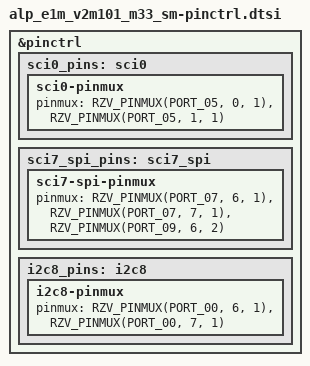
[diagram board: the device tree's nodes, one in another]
/*
 * Copyright (c) 2026 Alp Lab AB
 * SPDX-License-Identifier: Apache-2.0
 */

#include <zephyr/dt-bindings/gpio/gpio.h>
#include <zephyr/dt-bindings/pinctrl/renesas/pinctrl-rzv2n.h>

&pinctrl {
	/* SCI_UART0 console: P50 TXD / P51 RXD */
	sci0_pins: sci0 {
		sci0-pinmux {
			pinmux = <RZV_PINMUX(PORT_05, 0, 1)>, /* TXD */
				 <RZV_PINMUX(PORT_05, 1, 1)>; /* RXD */
		};
	};

	/*
	 * GD32G553 SPI fast path on SCI channel 7 (clock-synchronous Simple-SPI).
	 * Per the RZ/V2N PFC (Table 1.2-3): P76 = TXD7_MOSI7 (func1), P77 =
	 * RXD7_MISO7 (func1), P96 = SCK7 (func2).  Calibrated against the known-good
	 * console pin P50 = TXD0 (func1) and the P52 TXD1/SCK0/DE0/CTS0N column run.
	 *
	 * P97 (SS7) is deliberately NOT muxed here: master Simple-SPI has no
	 * hardware slave-select, so P97 is driven as a GPIO chip-select (gpio9 pin 7;
	 * see cs-gpios in the board dts).  Leaving it out keeps it in GPIO mode.
	 */
	sci7_spi_pins: sci7_spi {
		sci7-spi-pinmux {
			pinmux = <RZV_PINMUX(PORT_07, 6, 1)>, /* MOSI7 P76 */
				 <RZV_PINMUX(PORT_07, 7, 1)>, /* MISO7 P77 */
				 <RZV_PINMUX(PORT_09, 6, 2)>; /* SCK7  P96 */
		};
	};

	/* BRD_I2C (RIIC8): on-module GD32G553 I2C slave @ 0x70 */
	i2c8_pins: i2c8 {
		i2c8-pinmux {
			pinmux = <RZV_PINMUX(PORT_00, 6, 1)>, /* SDA P06 */
				 <RZV_PINMUX(PORT_00, 7, 1)>; /* SCL P07 */
		};
	};
};
